VERSION ""

NS_ :

BS_:

BU_: ABS_M4 Megaline_Gearbox MS4_ENGINE_ECU

BO_ 256 barrel_position: 8 Megaline_Gearbox
 SG_ gearpot : 8|10@1+ (4.888,0) [0|5000] "mV" Vector__XXX

BO_ 1472 acceleration: 8 ABS_M4
 SG_ ay : 48|16@1+ (0.00012742,-4.1768) [-4.7168|4.7167] "g" Vector__XXX
 SG_ ax : 32|16@1+ (0.00012742,-4.1768) [-4.7168|4.7167] "g" Vector__XXX

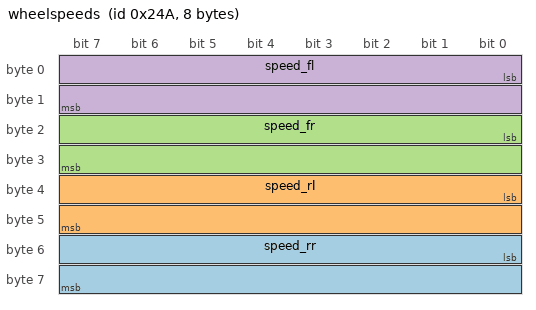
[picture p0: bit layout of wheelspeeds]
BO_ 586 wheelspeeds: 8 ABS_M4
 SG_ speed_rr : 48|16@1+ (0.015625,0) [0|100] "m/s" Vector__XXX
 SG_ speed_rl : 32|16@1+ (0.015625,0) [0|100] "m/s" Vector__XXX
 SG_ speed_fr : 16|16@1+ (0.015625,0) [0|100] "m/s" Vector__XXX
 SG_ speed_fl : 0|16@1+ (0.015625,0) [0|100] "m/s" Vector__XXX

CM_ SG_ 256 gearpot "Voltage of barrel possition sensor. Main sensor for AGS system";
BA_DEF_ BO_  "Quantisierung" STRING ;
BA_DEF_  "BusType" STRING ;
BA_DEF_DEF_  "Quantisierung" "CAN";
BA_DEF_DEF_  "BusType" "CAN";
